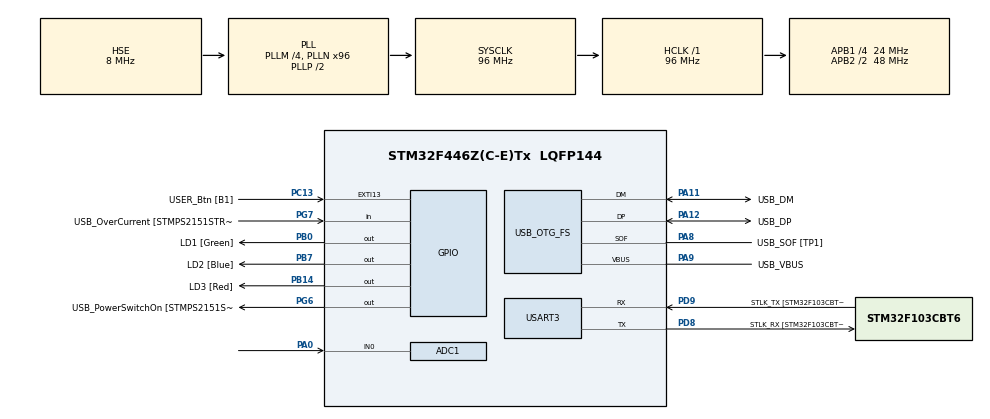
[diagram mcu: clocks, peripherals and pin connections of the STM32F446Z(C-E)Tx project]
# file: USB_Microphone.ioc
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ADC1.Channel-0\#ChannelRegularConversion=ADC_CHANNEL_0
ADC1.DMAContinuousRequests=ENABLE
ADC1.ExternalTrigConv=ADC_EXTERNALTRIGCONV_T8_TRGO
ADC1.NbrOfConversionFlag=1
ADC1.Rank-0\#ChannelRegularConversion=1
ADC1.SamplingTime-0\#ChannelRegularConversion=ADC_SAMPLETIME_3CYCLES
ADC1.master=1
Dma.ADC1.0.Direction=DMA_PERIPH_TO_MEMORY
Dma.ADC1.0.FIFOMode=DMA_FIFOMODE_DISABLE
Dma.ADC1.0.Instance=DMA2_Stream0
Dma.ADC1.0.MemDataAlignment=DMA_MDATAALIGN_HALFWORD
Dma.ADC1.0.MemInc=DMA_MINC_ENABLE
Dma.ADC1.0.Mode=DMA_CIRCULAR
Dma.ADC1.0.PeriphDataAlignment=DMA_PDATAALIGN_HALFWORD
Dma.ADC1.0.PeriphInc=DMA_PINC_DISABLE
Dma.ADC1.0.Priority=DMA_PRIORITY_LOW
Dma.Request0=ADC1
Mcu.Family=STM32F4
Mcu.Name=STM32F446Z(C-E)Tx
Mcu.Package=LQFP144
NVIC.DMA2_Stream0_IRQn=true\:0\:0\:false\:false\:true\:false\:true
NVIC.OTG_FS_IRQn=true\:0\:0\:false\:false\:true\:false\:true
NVIC.PriorityGroup=NVIC_PRIORITYGROUP_4
PA0-WKUP.Signal=ADCx_IN0
PA10.GPIO_Label=USB_ID
PA10.Signal=USB_OTG_FS_ID
PA11.GPIO_Label=USB_DM
PA11.Mode=Device_Only
PA11.Signal=USB_OTG_FS_DM
PA12.GPIO_Label=USB_DP
PA12.Mode=Device_Only
PA12.Signal=USB_OTG_FS_DP
PA13.GPIO_Label=TMS
PA13.Mode=Serial_Wire
PA13.Signal=SYS_JTMS-SWDIO
PA14.GPIO_Label=TCK
PA14.Mode=Serial_Wire
PA14.Signal=SYS_JTCK-SWCLK
PA8.GPIO_Label=USB_SOF [TP1]
PA8.Mode=Activate_SOF_FS
PA8.Signal=USB_OTG_FS_SOF
PA9.GPIO_Label=USB_VBUS
PA9.Mode=Activate_VBUS
PA9.Signal=USB_OTG_FS_VBUS
PB0.GPIO_Label=LD1 [Green]
PB0.Signal=GPIO_Output
PB14.GPIO_Label=LD3 [Red]
PB14.Signal=GPIO_Output
PB7.GPIO_Label=LD2 [Blue]
PB7.Signal=GPIO_Output
PC13.GPIO_Label=USER_Btn [B1]
PC13.Signal=GPXTI13
PC14-OSC32_IN.Mode=LSE-External-Oscillator
PC14-OSC32_IN.Signal=RCC_OSC32_IN
PC15-OSC32_OUT.Mode=LSE-External-Oscillator
PC15-OSC32_OUT.Signal=RCC_OSC32_OUT
PD8.GPIO_Label=STLK_RX [STM32F103CBT6_PA3]
PD8.Mode=Asynchronous
PD8.Signal=USART3_TX
PD9.GPIO_Label=STLK_TX [STM32F103CBT6_PA2]
PD9.Mode=Asynchronous
PD9.Signal=USART3_RX
PG6.GPIO_Label=USB_PowerSwitchOn [STMPS2151STR_EN]
PG6.Signal=GPIO_Output
PG7.GPIO_Label=USB_OverCurrent [STMPS2151STR_FAULT]
PG7.Signal=GPIO_Input
PH0-OSC_IN.GPIO_Label=MCO [STM32F103CBT6_PA8]
PH0-OSC_IN.Mode=HSE-External-Clock-Source
PH0-OSC_IN.Signal=RCC_OSC_IN
PH1-OSC_OUT.Mode=HSE-External-Clock-Source
PH1-OSC_OUT.Signal=RCC_OSC_OUT
ProjectManager.HeapSize=0x4000
ProjectManager.StackSize=0x2000
ProjectManager.TargetToolchain=STM32CubeIDE
RCC.48MHZClocksFreq_Value=24000000
RCC.AHBFreq_Value=96000000
RCC.APB1CLKDivider=RCC_HCLK_DIV4
RCC.APB1Freq_Value=24000000
RCC.APB1TimFreq_Value=48000000
RCC.APB2CLKDivider=RCC_HCLK_DIV2
RCC.APB2Freq_Value=48000000
RCC.APB2TimFreq_Value=96000000
RCC.CortexFreq_Value=96000000
RCC.HCLKFreq_Value=96000000
RCC.HSE_VALUE=8000000
RCC.HSI_VALUE=16000000
RCC.PLLM=4
RCC.PLLMUL=RCC_PLL_MUL9
RCC.PLLN=96
RCC.PLLQ=4
RCC.PRESCALERUSB=RCC_USBCLKSOURCE_PLL_DIV1_5
RCC.SYSCLKFreq_VALUE=96000000
RCC.SYSCLKSource=RCC_SYSCLKSOURCE_PLLCLK
RCC.SYSCLKSourceVirtual=RCC_SYSCLKSOURCE_PLLCLK
RCC.USBFreq_Value=48000000
RCC.VCOOutputFreq_Value=192000000
SH.ADCx_IN0.0=ADC1_IN0,IN0
TIM8.Period=124
TIM8.TIM_MasterOutputTrigger=TIM_TRGO_UPDATE
USART3.VirtualMode=VM_ASYNC
USB_DEVICE.CLASS_NAME_FS=AUDIO
USB_DEVICE.USBD_AUDIO_FREQ-AUDIO_FS=48000
USB_DEVICE.VirtualMode-AUDIO_FS=Audio
USB_DEVICE.VirtualModeFS=Audio_FS
USB_OTG_FS.VirtualMode=Device_Only
VP_TIM8_VS_ClockSourceINT.Mode=Internal
VP_USB_DEVICE_VS_USB_DEVICE_AUDIO_FS.Mode=AUDIO_FS
board=NUCLEO-F446ZE

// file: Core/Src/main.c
/* USER CODE BEGIN Header */
/**
  ******************************************************************************
  * @file           : main.c
  * @brief          : Main program body
  ******************************************************************************
  * @attention
  *
  * <h2><center>&copy; Copyright (c) 2021 STMicroelectronics.
  * All rights reserved.</center></h2>
  *
  * This software component is licensed by ST under Ultimate Liberty license
  * SLA0044, the "License"; You may not use this file except in compliance with
  * the License. You may obtain a copy of the License at:
  *                             www.st.com/SLA0044
  *
  ******************************************************************************
  */
/* USER CODE END Header */
#include "main.h"
#include "usb_device.h"
#include "usbd_audio.h"

/* USER CODE BEGIN PM */
#define OSA_BUF_SIZE 16
extern USBD_HandleTypeDef hUsbDeviceFS;
int16_t adc_buffer[OSA_BUF_SIZE * AUDIO_IN_PACKET / 2] = {0};
/* USER CODE END PM */

ADC_HandleTypeDef hadc1;
DMA_HandleTypeDef hdma_adc1;

TIM_HandleTypeDef htim8;

UART_HandleTypeDef huart3;

void SystemClock_Config(void);
static void MX_GPIO_Init(void);
static void MX_DMA_Init(void);
static void MX_ADC1_Init(void);
static void MX_USART3_UART_Init(void);
static void MX_TIM8_Init(void);

/* USER CODE BEGIN 0 */

void ADC_to_MIC(void)
{
	HAL_ADC_Start_DMA(&hadc1, (uint32_t*)adc_buffer, OSA_BUF_SIZE * (AUDIO_IN_PACKET / 2)); // Start ADC transfer into oversampling buffer
}

void HAL_ADC_ConvCpltCallback(ADC_HandleTypeDef* hadc) {
  USBD_AUDIO_HandleTypeDef *haudio = hUsbDeviceFS.pClassData;
  int16_t *buf_part = haudio->in_buffer + (AUDIO_IN_PACKET / 2) * haudio->in_buffer_half;  // USB mic buffer access

  /* Oversample for +2 bits */
  for (uint16_t i = 0; i < (AUDIO_IN_PACKET / 2); i++) {
  int32_t avg_value = 0;
    for (uint16_t j = 0; j < OSA_BUF_SIZE; j++) {
      avg_value += adc_buffer[OSA_BUF_SIZE * i + j];
    }
    // bit shift for signed variables is undefined behaviour
    // Don't forget the mic amp offset: 1.25V (6826 ADC value)
    buf_part[i] = (avg_value / 4) - 6826;
  }
}

/* USER CODE END 0 */

int main(void)
{

  /* MCU Configuration--------------------------------------------------------*/

  /* Reset of all peripherals, Initializes the Flash interface and the Systick. */
  HAL_Init();

  /* Configure the system clock */
  SystemClock_Config();

  /* Initialize all configured peripherals */
  MX_GPIO_Init();
  MX_DMA_Init();
  MX_ADC1_Init();
  MX_USART3_UART_Init();
  MX_USB_DEVICE_Init();
  MX_TIM8_Init();
  /* USER CODE BEGIN 2 */

  HAL_TIM_Base_Start(&htim8);

  /* USER CODE END 2 */

  /* Infinite loop */
  while (1)
  {

  }
}

void SystemClock_Config(void)
{
  RCC_OscInitTypeDef RCC_OscInitStruct = {0};
  RCC_ClkInitTypeDef RCC_ClkInitStruct = {0};
  RCC_PeriphCLKInitTypeDef PeriphClkInitStruct = {0};

  /** Configure the main internal regulator output voltage
  */
  __HAL_RCC_PWR_CLK_ENABLE();
  __HAL_PWR_VOLTAGESCALING_CONFIG(PWR_REGULATOR_VOLTAGE_SCALE3);
  /** Initializes the RCC Oscillators according to the specified parameters
  * in the RCC_OscInitTypeDef structure.
  */
  RCC_OscInitStruct.OscillatorType = RCC_OSCILLATORTYPE_HSE;
  RCC_OscInitStruct.HSEState = RCC_HSE_BYPASS;
  RCC_OscInitStruct.PLL.PLLState = RCC_PLL_ON;
  RCC_OscInitStruct.PLL.PLLSource = RCC_PLLSOURCE_HSE;
  RCC_OscInitStruct.PLL.PLLM = 4;
  RCC_OscInitStruct.PLL.PLLN = 96;
  RCC_OscInitStruct.PLL.PLLP = RCC_PLLP_DIV2;
  RCC_OscInitStruct.PLL.PLLQ = 4;
  RCC_OscInitStruct.PLL.PLLR = 2;
  if (HAL_RCC_OscConfig(&RCC_OscInitStruct) != HAL_OK)
  {
    Error_Handler();
  }
  /** Initializes the CPU, AHB and APB buses clocks
  */
  RCC_ClkInitStruct.ClockType = RCC_CLOCKTYPE_HCLK|RCC_CLOCKTYPE_SYSCLK
                              |RCC_CLOCKTYPE_PCLK1|RCC_CLOCKTYPE_PCLK2;
  RCC_ClkInitStruct.SYSCLKSource = RCC_SYSCLKSOURCE_PLLCLK;
  RCC_ClkInitStruct.AHBCLKDivider = RCC_SYSCLK_DIV1;
  RCC_ClkInitStruct.APB1CLKDivider = RCC_HCLK_DIV4;
  RCC_ClkInitStruct.APB2CLKDivider = RCC_HCLK_DIV2;

  if (HAL_RCC_ClockConfig(&RCC_ClkInitStruct, FLASH_LATENCY_3) != HAL_OK)
  {
    Error_Handler();
  }
  PeriphClkInitStruct.PeriphClockSelection = RCC_PERIPHCLK_CLK48;
  PeriphClkInitStruct.Clk48ClockSelection = RCC_CLK48CLKSOURCE_PLLQ;
  if (HAL_RCCEx_PeriphCLKConfig(&PeriphClkInitStruct) != HAL_OK)
  {
    Error_Handler();
  }
}

static void MX_ADC1_Init(void)
{

  ADC_ChannelConfTypeDef sConfig = {0};

  /** Configure the global features of the ADC (Clock, Resolution, Data Alignment and number of conversion)
  */
  hadc1.Instance = ADC1;
  hadc1.Init.ClockPrescaler = ADC_CLOCK_SYNC_PCLK_DIV2;
  hadc1.Init.Resolution = ADC_RESOLUTION_12B;
  hadc1.Init.ScanConvMode = DISABLE;
  hadc1.Init.ContinuousConvMode = DISABLE;
  hadc1.Init.DiscontinuousConvMode = DISABLE;
  hadc1.Init.ExternalTrigConvEdge = ADC_EXTERNALTRIGCONVEDGE_RISING;
  hadc1.Init.ExternalTrigConv = ADC_EXTERNALTRIGCONV_T8_TRGO;
  hadc1.Init.DataAlign = ADC_DATAALIGN_RIGHT;
  hadc1.Init.NbrOfConversion = 1;
  hadc1.Init.DMAContinuousRequests = ENABLE;
  hadc1.Init.EOCSelection = ADC_EOC_SINGLE_CONV;
  if (HAL_ADC_Init(&hadc1) != HAL_OK)
  {
    Error_Handler();
  }
  /** Configure for the selected ADC regular channel its corresponding rank in the sequencer and its sample time.
  */
  sConfig.Channel = ADC_CHANNEL_0;
  sConfig.Rank = 1;
  sConfig.SamplingTime = ADC_SAMPLETIME_3CYCLES;
  if (HAL_ADC_ConfigChannel(&hadc1, &sConfig) != HAL_OK)
  {
    Error_Handler();
  }

}

static void MX_TIM8_Init(void)
{

  TIM_ClockConfigTypeDef sClockSourceConfig = {0};
  TIM_MasterConfigTypeDef sMasterConfig = {0};

  htim8.Instance = TIM8;
  htim8.Init.Prescaler = 0;
  htim8.Init.CounterMode = TIM_COUNTERMODE_UP;
  htim8.Init.Period = 124;
  htim8.Init.ClockDivision = TIM_CLOCKDIVISION_DIV1;
  htim8.Init.RepetitionCounter = 0;
  htim8.Init.AutoReloadPreload = TIM_AUTORELOAD_PRELOAD_DISABLE;
  if (HAL_TIM_Base_Init(&htim8) != HAL_OK)
  {
    Error_Handler();
  }
  sClockSourceConfig.ClockSource = TIM_CLOCKSOURCE_INTERNAL;
  if (HAL_TIM_ConfigClockSource(&htim8, &sClockSourceConfig) != HAL_OK)
  {
    Error_Handler();
  }
  sMasterConfig.MasterOutputTrigger = TIM_TRGO_UPDATE;
  sMasterConfig.MasterSlaveMode = TIM_MASTERSLAVEMODE_DISABLE;
  if (HAL_TIMEx_MasterConfigSynchronization(&htim8, &sMasterConfig) != HAL_OK)
  {
    Error_Handler();
  }

}

static void MX_USART3_UART_Init(void)
{

  huart3.Instance = USART3;
  huart3.Init.BaudRate = 115200;
  huart3.Init.WordLength = UART_WORDLENGTH_8B;
  huart3.Init.StopBits = UART_STOPBITS_1;
  huart3.Init.Parity = UART_PARITY_NONE;
  huart3.Init.Mode = UART_MODE_TX_RX;
  huart3.Init.HwFlowCtl = UART_HWCONTROL_NONE;
  huart3.Init.OverSampling = UART_OVERSAMPLING_16;
  if (HAL_UART_Init(&huart3) != HAL_OK)
  {
    Error_Handler();
  }

}

static void MX_DMA_Init(void)
{

  /* DMA controller clock enable */
  __HAL_RCC_DMA2_CLK_ENABLE();

  /* DMA interrupt init */
  /* DMA2_Stream0_IRQn interrupt configuration */
  HAL_NVIC_SetPriority(DMA2_Stream0_IRQn, 0, 0);
  HAL_NVIC_EnableIRQ(DMA2_Stream0_IRQn);

}

static void MX_GPIO_Init(void)
{
  GPIO_InitTypeDef GPIO_InitStruct = {0};

  /* GPIO Ports Clock Enable */
  __HAL_RCC_GPIOC_CLK_ENABLE();
  __HAL_RCC_GPIOH_CLK_ENABLE();
  __HAL_RCC_GPIOA_CLK_ENABLE();
  __HAL_RCC_GPIOB_CLK_ENABLE();
  __HAL_RCC_GPIOD_CLK_ENABLE();
  __HAL_RCC_GPIOG_CLK_ENABLE();

  /*Configure GPIO pin Output Level */
  HAL_GPIO_WritePin(GPIOB, LD1_Pin|LD3_Pin|LD2_Pin, GPIO_PIN_RESET);

  /*Configure GPIO pin Output Level */
  HAL_GPIO_WritePin(USB_PowerSwitchOn_GPIO_Port, USB_PowerSwitchOn_Pin, GPIO_PIN_RESET);

  /*Configure GPIO pin : USER_Btn_Pin */
  GPIO_InitStruct.Pin = USER_Btn_Pin;
  GPIO_InitStruct.Mode = GPIO_MODE_IT_RISING;
  GPIO_InitStruct.Pull = GPIO_NOPULL;
  HAL_GPIO_Init(USER_Btn_GPIO_Port, &GPIO_InitStruct);

  /*Configure GPIO pins : LD1_Pin LD3_Pin LD2_Pin */
  GPIO_InitStruct.Pin = LD1_Pin|LD3_Pin|LD2_Pin;
  GPIO_InitStruct.Mode = GPIO_MODE_OUTPUT_PP;
  GPIO_InitStruct.Pull = GPIO_NOPULL;
  GPIO_InitStruct.Speed = GPIO_SPEED_FREQ_LOW;
  HAL_GPIO_Init(GPIOB, &GPIO_InitStruct);

  /*Configure GPIO pin : USB_PowerSwitchOn_Pin */
  GPIO_InitStruct.Pin = USB_PowerSwitchOn_Pin;
  GPIO_InitStruct.Mode = GPIO_MODE_OUTPUT_PP;
  GPIO_InitStruct.Pull = GPIO_NOPULL;
  GPIO_InitStruct.Speed = GPIO_SPEED_FREQ_LOW;
  HAL_GPIO_Init(USB_PowerSwitchOn_GPIO_Port, &GPIO_InitStruct);

  /*Configure GPIO pin : USB_OverCurrent_Pin */
  GPIO_InitStruct.Pin = USB_OverCurrent_Pin;
  GPIO_InitStruct.Mode = GPIO_MODE_INPUT;
  GPIO_InitStruct.Pull = GPIO_NOPULL;
  HAL_GPIO_Init(USB_OverCurrent_GPIO_Port, &GPIO_InitStruct);

}

void Error_Handler(void)
{
  __disable_irq();
  while (1)
  {
  }
}

/************************ (C) COPYRIGHT STMicroelectronics *****END OF FILE****/
